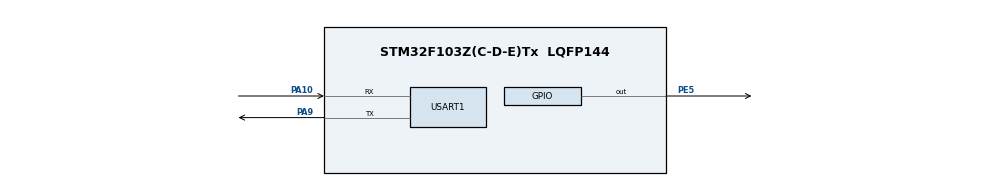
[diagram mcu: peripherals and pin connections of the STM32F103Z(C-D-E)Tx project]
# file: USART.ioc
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Mcu.Family=STM32F1
Mcu.Name=STM32F103Z(C-D-E)Tx
Mcu.Package=LQFP144
NVIC.PriorityGroup=NVIC_PRIORITYGROUP_4
PA10.Mode=Asynchronous
PA10.Signal=USART1_RX
PA9.Mode=Asynchronous
PA9.Signal=USART1_TX
PE5.Signal=GPIO_Output
ProjectManager.HeapSize=0x200
ProjectManager.StackSize=0x400
ProjectManager.TargetToolchain=MDK-ARM V5.32
RCC.APB1Freq_Value=8000000
RCC.APB2Freq_Value=8000000
USART1.VirtualMode=VM_ASYNC
VP_SYS_VS_ND.Mode=No_Debug
board=custom

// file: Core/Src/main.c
/* USER CODE BEGIN Header */
/**
  ******************************************************************************
  * @file           : main.c
  * @brief          : Main program body
  ******************************************************************************
  * @attention
  *
  * Copyright (c) 2024 STMicroelectronics.
  * All rights reserved.
  *
  * This software is licensed under terms that can be found in the LICENSE file
  * in the root directory of this software component.
  * If no LICENSE file comes with this software, it is provided AS-IS.
  *
  ******************************************************************************
  */
/* USER CODE END Header */
#include "main.h"
#include "usart.h"
#include "gpio.h"

/* USER CODE BEGIN Includes */
#include <stdio.h>
/* USER CODE END Includes */

void SystemClock_Config(void);

/* USER CODE BEGIN 0 */
int fputc(int ch, FILE *f){
	uint8_t temp[1] = {ch};
	HAL_UART_Transmit(&huart1, temp, 1, 2);
	return ch;
}
/* USER CODE END 0 */

int main(void)
{
  /* USER CODE BEGIN 1 */
  uint8_t Tran_Data[7] = "yoshino";
  uint8_t Rece_Data[50];
  /* USER CODE END 1 */

  /* MCU Configuration--------------------------------------------------------*/

  /* Reset of all peripherals, Initializes the Flash interface and the Systick. */
  HAL_Init();

  /* Configure the system clock */
  SystemClock_Config();

  /* Initialize all configured peripherals */
  MX_GPIO_Init();
  MX_USART1_UART_Init();

  /* Infinite loop */
  /* USER CODE BEGIN WHILE */
  while (1)
  {
	  HAL_UART_Receive(&huart1, Rece_Data, 50, 50);
	  if (Rece_Data[0] != '\0'){
	  HAL_UART_Transmit(&huart1, Tran_Data, 50, 50);
	  HAL_Delay(50);
	  HAL_UART_Transmit(&huart1, Rece_Data, 50, 50);
	  }
    /* USER CODE END WHILE */

    /* USER CODE BEGIN 3 */
	  HAL_GPIO_WritePin(GPIOE,GPIO_PIN_5,GPIO_PIN_RESET);
	  memset(Rece_Data, 0, sizeof(Rece_Data));
	  HAL_Delay(500);
	  HAL_GPIO_WritePin(GPIOE,GPIO_PIN_5,GPIO_PIN_SET);
  }
  /* USER CODE END 3 */
}

void SystemClock_Config(void)
{
  RCC_OscInitTypeDef RCC_OscInitStruct = {0};
  RCC_ClkInitTypeDef RCC_ClkInitStruct = {0};

  /** Initializes the RCC Oscillators according to the specified parameters
  * in the RCC_OscInitTypeDef structure.
  */
  RCC_OscInitStruct.OscillatorType = RCC_OSCILLATORTYPE_HSI;
  RCC_OscInitStruct.HSIState = RCC_HSI_ON;
  RCC_OscInitStruct.HSICalibrationValue = RCC_HSICALIBRATION_DEFAULT;
  RCC_OscInitStruct.PLL.PLLState = RCC_PLL_NONE;
  if (HAL_RCC_OscConfig(&RCC_OscInitStruct) != HAL_OK)
  {
    Error_Handler();
  }

  /** Initializes the CPU, AHB and APB buses clocks
  */
  RCC_ClkInitStruct.ClockType = RCC_CLOCKTYPE_HCLK|RCC_CLOCKTYPE_SYSCLK
                              |RCC_CLOCKTYPE_PCLK1|RCC_CLOCKTYPE_PCLK2;
  RCC_ClkInitStruct.SYSCLKSource = RCC_SYSCLKSOURCE_HSI;
  RCC_ClkInitStruct.AHBCLKDivider = RCC_SYSCLK_DIV1;
  RCC_ClkInitStruct.APB1CLKDivider = RCC_HCLK_DIV1;
  RCC_ClkInitStruct.APB2CLKDivider = RCC_HCLK_DIV1;

  if (HAL_RCC_ClockConfig(&RCC_ClkInitStruct, FLASH_LATENCY_0) != HAL_OK)
  {
    Error_Handler();
  }
}

void Error_Handler(void)
{
  __disable_irq();
  while (1)
  {
  }
}
